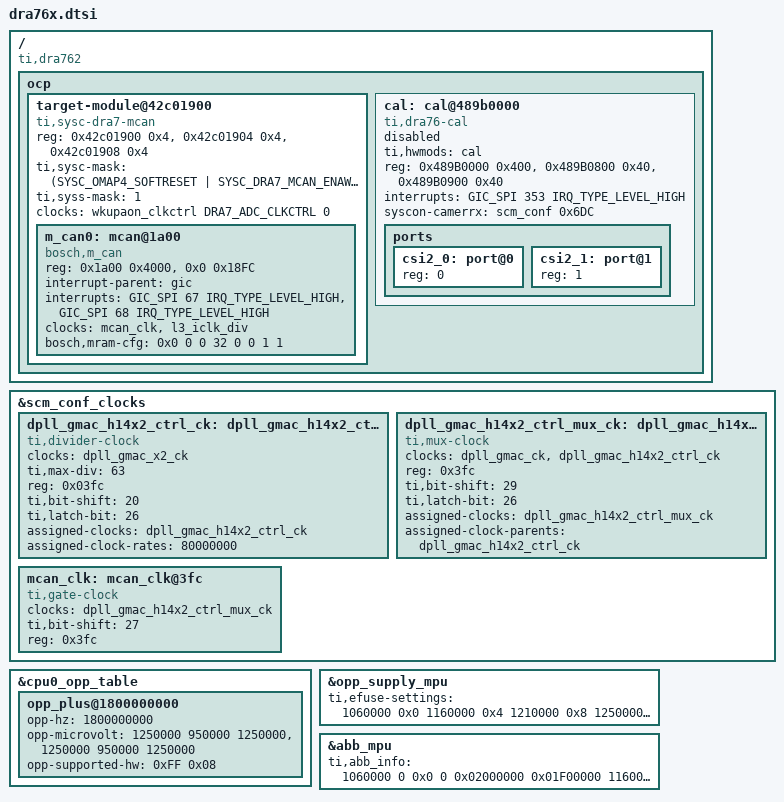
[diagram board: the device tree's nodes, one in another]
/*
 * Copyright (C) 2017 Texas Instruments Incorporated - http://www.ti.com/
 *
 * This program is free software; you can redistribute it and/or modify
 * it under the terms of the GNU General Public License version 2 as
 * published by the Free Software Foundation.
 */

#include "dra74x-p.dtsi"

/ {
	compatible = "ti,dra762", "ti,dra7";

	ocp {
		target-module@42c01900 {
			compatible = "ti,sysc-dra7-mcan", "ti,sysc";
			ranges = <0x0 0x42c00000 0x2000>;
			#address-cells = <1>;
			#size-cells = <1>;
			reg = <0x42c01900 0x4>,
			      <0x42c01904 0x4>,
			      <0x42c01908 0x4>;
			reg-names = "rev", "sysc", "syss";
			ti,sysc-mask = <(SYSC_OMAP4_SOFTRESET |
					 SYSC_DRA7_MCAN_ENAWAKEUP)>;
			ti,syss-mask = <1>;
			clocks = <&wkupaon_clkctrl DRA7_ADC_CLKCTRL 0>;
			clock-names = "fck";

			m_can0: mcan@1a00 {
				compatible = "bosch,m_can";
				reg = <0x1a00 0x4000>, <0x0 0x18FC>;
				reg-names = "m_can", "message_ram";
				interrupt-parent = <&gic>;
				interrupts = <GIC_SPI 67 IRQ_TYPE_LEVEL_HIGH>,
					     <GIC_SPI 68 IRQ_TYPE_LEVEL_HIGH>;
				interrupt-names = "int0", "int1";
				clocks = <&mcan_clk>, <&l3_iclk_div>;
				clock-names = "cclk", "hclk";
				bosch,mram-cfg = <0x0 0 0 32 0 0 1 1>;
			};
		};

		cal: cal@489b0000 {
			compatible = "ti,dra76-cal";
			ti,hwmods = "cal";
			reg = <0x489B0000 0x400>,
			      <0x489B0800 0x40>,
			      <0x489B0900 0x40>;
				reg-names = "cal_top",
					    "cal_rx_core0",
					    "cal_rx_core1";
			interrupts = <GIC_SPI 353 IRQ_TYPE_LEVEL_HIGH>;
			syscon-camerrx = <&scm_conf 0x6DC>;
			#address-cells = <1>;
			#size-cells = <0>;
			status = "disabled";

			ports {
				#address-cells = <1>;
				#size-cells = <0>;

				csi2_0: port@0 {
					reg = <0>;
				};
				csi2_1: port@1 {
					reg = <1>;
				};
			};
		};
	};

};

&scm_conf_clocks {
	dpll_gmac_h14x2_ctrl_ck: dpll_gmac_h14x2_ctrl_ck@3fc {
		#clock-cells = <0>;
		compatible = "ti,divider-clock";
		clocks = <&dpll_gmac_x2_ck>;
		ti,max-div = <63>;
		reg = <0x03fc>;
		ti,bit-shift=<20>;
		ti,latch-bit=<26>;
		assigned-clocks = <&dpll_gmac_h14x2_ctrl_ck>;
		assigned-clock-rates = <80000000>;
	};

	dpll_gmac_h14x2_ctrl_mux_ck: dpll_gmac_h14x2_ctrl_mux_ck@3fc {
		#clock-cells = <0>;
		compatible = "ti,mux-clock";
		clocks = <&dpll_gmac_ck>, <&dpll_gmac_h14x2_ctrl_ck>;
		reg = <0x3fc>;
		ti,bit-shift = <29>;
		ti,latch-bit=<26>;
		assigned-clocks = <&dpll_gmac_h14x2_ctrl_mux_ck>;
		assigned-clock-parents = <&dpll_gmac_h14x2_ctrl_ck>;
	};

	mcan_clk: mcan_clk@3fc {
		#clock-cells = <0>;
		compatible = "ti,gate-clock";
		clocks = <&dpll_gmac_h14x2_ctrl_mux_ck>;
		ti,bit-shift = <27>;
		reg = <0x3fc>;
	};
};

&cpu0_opp_table {
	opp_plus@1800000000 {
		opp-hz = /bits/ 64 <1800000000>;
		opp-microvolt = <1250000 950000 1250000>,
				<1250000 950000 1250000>;
		opp-supported-hw = <0xFF 0x08>;
	};
};

&opp_supply_mpu {
	ti,efuse-settings = <
	/* uV   offset */
	1060000 0x0
	1160000 0x4
	1210000 0x8
	1250000 0xC
	>;
};

&abb_mpu {
	ti,abb_info = <
	/*uV		ABB	efuse	rbb_m fbb_m	vset_m*/
	1060000		0	0x0	0 0x02000000 0x01F00000
	1160000		0	0x4	0 0x02000000 0x01F00000
	1210000		0	0x8	0 0x02000000 0x01F00000
	1250000		0	0xC	0 0x02000000 0x01F00000
	>;
};
